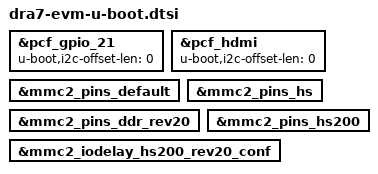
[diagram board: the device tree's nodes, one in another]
// SPDX-License-Identifier: GPL-2.0+
/*
 * Copyright (C) 2017 Texas Instruments Incorporated - http://www.ti.com/
 */

#include "omap5-u-boot.dtsi"

&pcf_gpio_21{
	u-boot,i2c-offset-len = <0>;
};

&pcf_hdmi{
	u-boot,i2c-offset-len = <0>;
};

&mmc2_pins_default {
	u-boot,dm-spl;
};

&mmc2_pins_hs {
	u-boot,dm-spl;
};

&mmc2_pins_ddr_rev20 {
	u-boot,dm-spl;
};

&mmc2_pins_hs200 {
	u-boot,dm-spl;
};

&mmc2_iodelay_hs200_rev20_conf {
	u-boot,dm-spl;
};
